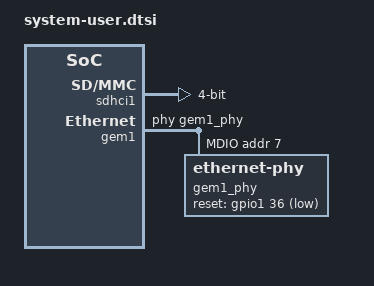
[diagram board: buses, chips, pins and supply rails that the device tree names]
/******************************************************************************
* Copyright (C) 2020-2022 Xilinx, Inc. All rights reserved.
* Copyright (C) 2022-2025 Advanced Micro Devices, Inc. All rights reserved.
* SPDX-License-Identifier: MIT
******************************************************************************/
/*
 * /include/ "system-conf.dtsi"
 * Adding directly contents of system-conf file until CR-1139794 is fixed
 */
#include "include/dt-bindings/gpio/gpio.h"

/ {
	chosen {
		bootargs = "console=ttyAMA0 earlycon=pl011,mmio32,0xFF010000,115200n8 clk_ignore_unused root=PARTUUID=6812d01f-f2ab-48a6-b218-8f56f2f72dad rw rootwait cma=512M";
		stdout-path = "serial0:115200n8";
	};
};

&sdhci1 {
	bus-width = <4>;
	xlnx,bus-width = <4>;
	disable-wp;
	no-1-8-v;
	max-frequency = <25000000>;
	clk-phase-sd-hs = <0>, <0>;
	resets = <&versal_reset 0x0c104030>; /* VERSAL_RST_SDIO_1 */
};

&gem1 {
	phy-handle = <&gem1_phy>;

	mdio {
		#address-cells = <1>;
		#size-cells = <0>;
		status = "okay";

		gem1_phy: ethernet-phy@7 {
			reg = <7>;
			reset-gpios = <&gpio1 36 GPIO_ACTIVE_LOW>;
			reset-assert-us = <10000>;
			reset-deassert-us = <50000>;
		};
	};
};

&amba_pl {
	/delete-property/ firmware-name;
};
